AUTOSAR XML (schema 4-3-0)
package /Impl_SWC_HALIN_ARPkg
  swc implementation Impl_SWC_HALIN_type: programming-language=C, sw-version=1.0.0, vendor-id=0, behavior=SWC_HALIN_type_IB
    code-descriptors:
      code SRC: artifact-descriptors=autosar-engineering-object={short-label=EngObject, category=SWSRC}
    resource consumption ResourceConsumption
      memory section Mem_SWC_HALIN_CAL: size=0, sw-addrmethod=CAL, symbol=CAL
      memory section Mem_SWC_HALIN_CODE: size=0, sw-addrmethod=CODE, symbol=CODE
package /Impl_Type_HALIN_ARPkg
  6 x impl type:
    BHAL_CAN1_outputs: category=STRUCTURE
      63 x element, all with category=TYPE_REFERENCE:
        VHAL_CANMsgInvalidACBTMSC10000_flg: implementation-data-type=boolean
        VHAL_ACAmbTemp_C: implementation-data-type=float32
        VHAL_CANMsgInvalidACBTMSC10001_flg: implementation-data-type=boolean
        VHAL_ACFanSpdSta_enum: implementation-data-type=uint8
        VHAL_CANMsgInvalidACBTMSC10004_flg: implementation-data-type=boolean
        VHAL_TM2BFaultCode_enum: implementation-data-type=uint8
        VHAL_CANMsgInvalidACBTMSC50000_flg: implementation-data-type=boolean
        VHAL_ACTempSetSta_C: implementation-data-type=float32
        VHAL_CANMsgInvalidASC1A_flg: implementation-data-type=boolean
        VHAL_ASC1KneelingInfo_enum: implementation-data-type=uint8
        VHAL_CANMsgInvalidEBC1_flg: implementation-data-type=boolean
        VHAL_ABSFullyOper_enum: implementation-data-type=uint8
        VHAL_ABSOffroadSw_enum: implementation-data-type=uint8
        VHAL_ASRBrakeCtrlAtc_enum: implementation-data-type=uint8
        VHAL_ASREngCtrlAtc_enum: implementation-data-type=uint8
        VHAL_ASRHillHolderSw_enum: implementation-data-type=uint8
        VHAL_ASROffroadSw_enum: implementation-data-type=uint8
        VHAL_ATCASRInfoSig_enum: implementation-data-type=uint8
        VHAL_AcltrInterlockSw_enum: implementation-data-type=uint8
        VHAL_AntiLBrakABSAct_enum: implementation-data-type=uint8
        VHAL_BrakePedalPos_pct: implementation-data-type=float32
        VHAL_EBSAmWarnLampSta_enum: implementation-data-type=uint8
        VHAL_EBSBrakeSw_enum: implementation-data-type=uint8
        VHAL_EBSRedWarnLampSta_enum: implementation-data-type=uint8
        VHAL_EngAuxShutdownSw_enum: implementation-data-type=uint8
        VHAL_EngDerateSw_enum: implementation-data-type=uint8
        VHAL_EngRetSel_pct: implementation-data-type=float32
        VHAL_HaltBrakeSw_enum: implementation-data-type=uint8
        VHAL_RmAccelEnSw_enum: implementation-data-type=uint8
        VHAL_SACtrlBrakeCtrl_SA: implementation-data-type=float32
        VHAL_TractCtrlOvrSw_enum: implementation-data-type=uint8
        VHAL_TrailerABSSta_enum: implementation-data-type=uint8
        VHAL_TrailerABSWarnSig_enum: implementation-data-type=uint8
        VHAL_CANMsgInvalidEBC2_flg: implementation-data-type=boolean
        VHAL_FASpeed_kph: implementation-data-type=float32
        VHAL_RelaSpdFALWheel_kph: implementation-data-type=float32
        VHAL_RelaSpdFARWheel_kph: implementation-data-type=float32
        VHAL_CANMsgInvalidEBC5_flg: implementation-data-type=boolean
        VHAL_BrkTempeWarn_enum: implementation-data-type=uint8
        VHAL_FndBrkUse_enum: implementation-data-type=uint8
        VHAL_HaltBrkMode_enum: implementation-data-type=uint8
        VHAL_HillHolderMode_enum: implementation-data-type=uint8
        VHAL_ParkBrkActuFAct_enum: implementation-data-type=uint8
        VHAL_XBRAcltnLimit_mps2: implementation-data-type=float32
        VHAL_XBRActtrlMode_enum: implementation-data-type=uint8
        VHAL_XBRSysSta_enum: implementation-data-type=uint8
        VHAL_CANMsgInvalidECASDM1_flg: implementation-data-type=boolean
        VHAL_ECASAWarmLampSta_enum: implementation-data-type=uint8
        VHAL_CANMsgInvalidEMC1EM1_flg: implementation-data-type=boolean
        VHAL_EM1CS_enum: implementation-data-type=uint8
        VHAL_EM1Cnt_enum: implementation-data-type=uint8
        VHAL_EM1OvrCtrlMBrk_enum: implementation-data-type=uint8
        VHAL_EM1OvrCtrlMDriv_enum: implementation-data-type=uint8
        VHAL_EM1OvrCtrlMPriBrk_enum: implementation-data-type=uint8
        VHAL_EM1ReqTorqHRlsBrk_pct: implementation-data-type=float32
        VHAL_EM1ReqTorqHRlsDri_pct: implementation-data-type=float32
        VHAL_EM1ReqTorqLimBrk_pct: implementation-data-type=float32
        VHAL_EM1ReqTorqLimDriv_pct: implementation-data-type=float32
        VHAL_CANMsgInvalidHRW_flg: implementation-data-type=boolean
        VHAL_WhlSpeedFL_kph: implementation-data-type=float32
        VHAL_CANMsgInvalidTC1_flg: implementation-data-type=boolean
        VHAL_DrivDirF_enum: implementation-data-type=uint8
        VHAL_TransReqGear_enum: implementation-data-type=uint8
    BHAL_CAN2_outputs: category=STRUCTURE
      element VHAL_CANMsgInvalidIVIC1000_flg: implementation-data-type=boolean
      element VHAL_IVIACFanSpdReqCmd_enum: implementation-data-type=uint8
    BHAL_CAN3_outputs: category=STRUCTURE
      49 x element, all with category=TYPE_REFERENCE:
        VHAL_CANMsgInvalidB2TMInfo_flg: implementation-data-type=boolean
        VHAL_B2THVRlySta_enum: implementation-data-type=uint8
        VHAL_CANMsgInvalidB2VBattInfo1_flg: implementation-data-type=boolean
        VHAL_B2VBI1BattType_enum: implementation-data-type=uint8
        VHAL_CANMsgInvalidB2VCurrentLimit_flg: implementation-data-type=boolean
        VHAL_B2VAPlsDischgCurr_A: implementation-data-type=float32
        VHAL_B2VAvaPlsChgCurr_A: implementation-data-type=float32
        VHAL_CANMsgInvalidB2VFult132960_flg: implementation-data-type=boolean
        VHAL_B2VHVILFault_flg: implementation-data-type=boolean
        VHAL_CANMsgInvalidB2VST1_flg: implementation-data-type=boolean
        VHAL_B2VACChgConnSta_flg: implementation-data-type=boolean
        VHAL_B2VACChgNegRlySta_enum: implementation-data-type=uint8
        VHAL_B2VACChgPosRlySta_enum: implementation-data-type=uint8
        VHAL_B2VBMUHVSta_enum: implementation-data-type=uint8
        VHAL_B2VChgMode_enum: implementation-data-type=uint8
        VHAL_B2VChgSta_enum: implementation-data-type=uint8
        VHAL_B2VDCChgConnSta_enum: implementation-data-type=uint8
        VHAL_B2VDCChgN1RlySta_enum: implementation-data-type=uint8
        VHAL_B2VDCChgP1RlySta_enum: implementation-data-type=uint8
        VHAL_B2VMainNegRlySta_enum: implementation-data-type=uint8
        VHAL_CANMsgInvalidB2VST2_flg: implementation-data-type=boolean
        VHAL_B2VFaultCode_enum: implementation-data-type=uint8
        VHAL_B2VFaultLv_enum: implementation-data-type=uint8
        VHAL_B2VPackCurr_A: implementation-data-type=float32
        VHAL_B2VPackInsideVol_V: implementation-data-type=float32
        VHAL_B2VRqHVPwrOff_enum: implementation-data-type=uint8
        VHAL_B2VSOC_pct: implementation-data-type=float32
        VHAL_CANMsgInvalidB2VST4_flg: implementation-data-type=boolean
        VHAL_B2VMinTempPos_enum: implementation-data-type=uint8
        VHAL_CANMsgInvalidB2VST5_flg: implementation-data-type=boolean
        VHAL_B2VCellMinVol_V: implementation-data-type=float32
        VHAL_CANMsgInvalidEWP1_flg: implementation-data-type=boolean
        VHAL_EWPPEFault_enum: implementation-data-type=uint8
        VHAL_CANMsgInvalidTMMCUSta1_flg: implementation-data-type=boolean
        VHAL_AtvDisChgEnFbk_flg: implementation-data-type=boolean
        VHAL_MCUCtrlMdSta_enum: implementation-data-type=uint8
        VHAL_MCUIGBTEnFbk_flg: implementation-data-type=boolean
        VHAL_MotorSpd_rpm: implementation-data-type=float32
        VHAL_MotorTrq_Nm: implementation-data-type=float32
        VHAL_CANMsgInvalidTMMCUSta2_flg: implementation-data-type=boolean
        VHAL_MCUFailGrade_enum: implementation-data-type=uint8
        VHAL_MCUTemp_C: implementation-data-type=float32
        VHAL_MCUTrqLimHi_Nm: implementation-data-type=float32
        VHAL_MCUTrqLimLo_Nm: implementation-data-type=float32
        VHAL_MotorTemp_C: implementation-data-type=float32
        VHAL_CANMsgInvalidTMMCUSta3_flg: implementation-data-type=boolean
        VHAL_MCUDCCur_A: implementation-data-type=float32
        VHAL_MCUDCVol_V: implementation-data-type=float32
        VHAL_MCUFailCode_enum: implementation-data-type=uint8
    BHAL_CAN4_outputs: category=STRUCTURE
      51 x element, all with category=TYPE_REFERENCE:
        VHAL_CANMsgInvalidZFRC1000_flg: implementation-data-type=boolean
        VHAL_ParkBrakeSW_enum: implementation-data-type=uint8
        VHAL_CANMsgInvalidZFRCE1000_flg: implementation-data-type=boolean
        VHAL_AirPressureFC2_kPa: implementation-data-type=float32
        VHAL_ZFRBCMAutoLightSWSta_flg: implementation-data-type=boolean
        VHAL_ZFRBCMBrakeSta_flg: implementation-data-type=boolean
        VHAL_ZFRBCMHBeamSWSta_flg: implementation-data-type=boolean
        VHAL_ZFRBCMHeadLpSWSta_flg: implementation-data-type=boolean
        VHAL_ZFRBCMLFTurnLpCSta_A: implementation-data-type=float32
        VHAL_ZFRBCMLightSensorVSta_V: implementation-data-type=float32
        VHAL_ZFRBCMPLampSta_flg: implementation-data-type=boolean
        VHAL_ZFRBCMRFTurnLpCSta_A: implementation-data-type=float32
        VHAL_ZFRBCMRFogLpSWSta_flg: implementation-data-type=boolean
        VHAL_ZFRBCMSeatbeltSta_flg: implementation-data-type=boolean
        VHAL_ZFRBCMWasherSWSta_flg: implementation-data-type=boolean
        VHAL_ZFRBCMWiperASSta_flg: implementation-data-type=boolean
        VHAL_ZFRBCMWiperHSWSta_flg: implementation-data-type=boolean
        VHAL_ZFRBCMWiperLSWSta_flg: implementation-data-type=boolean
        VHAL_CANMsgInvalidZRRCE1000_flg: implementation-data-type=boolean
        VHAL_ZRRBCMAllDoorSta_enum: implementation-data-type=uint8
        VHAL_CANMsgInvalidZRRCE1001_flg: implementation-data-type=boolean
        VHAL_AirPressurePC3_kPa: implementation-data-type=float32
        VHAL_AirPressureRC1_kPa: implementation-data-type=float32
        VHAL_FDCCHASSISVCUEACPressSta_flg: implementation-data-type=boolean
        VHAL_ZRRBCMCallingSWSta_flg: implementation-data-type=boolean
        VHAL_ZRRBCMLRTurnLpCSta_A: implementation-data-type=float32
        VHAL_ZRRBCMPLampSta_flg: implementation-data-type=boolean
        VHAL_ZRRBCMRRTurnLpCSta_A: implementation-data-type=float32
        VHAL_ZRRBCMSTOPSW2Sta_flg: implementation-data-type=boolean
        VHAL_ZRRBCMSTOPSWSta_flg: implementation-data-type=boolean
        VHAL_CANMsgInvalidzGWCANRr1C500_flg: implementation-data-type=boolean
        VHAL_DCDCEnSta_enum: implementation-data-type=uint8
        VHAL_DCDCErrLvSta_enum: implementation-data-type=uint8
        VHAL_DCDCOutVolSta_V: implementation-data-type=float32
        VHAL_DCDCTempSta_C: implementation-data-type=float32
        VHAL_EACEnSta_enum: implementation-data-type=uint8
        VHAL_EACErrLvSta_enum: implementation-data-type=uint8
        VHAL_EACInvTempSta_C: implementation-data-type=float32
        VHAL_EHPSEnSta_enum: implementation-data-type=uint8
        VHAL_EHPSErrLvSta_enum: implementation-data-type=uint8
        VHAL_EHPSInvTempSta_C: implementation-data-type=float32
        VHAL_EHPSMotorSpdSta_rpm: implementation-data-type=float32
        VHAL_PDUACRlySta_enum: implementation-data-type=uint8
        VHAL_PDUDCDCEACEHPSHVLoopSta_enum: implementation-data-type=uint8
        VHAL_PDUDCDCEACEHPSPreRlySta_enum: implementation-data-type=uint8
        VHAL_PDUDCDCEACEHPSRlySta_enum: implementation-data-type=uint8
        VHAL_PDUHVILSta_enum: implementation-data-type=uint8
        VHAL_PDUMCUHVLoopSta_enum: implementation-data-type=uint8
        VHAL_PDUMCUPosRlySta_enum: implementation-data-type=uint8
        VHAL_PDUMCUPreRlySta_enum: implementation-data-type=uint8
        VHAL_PDUSelfChkSta_enum: implementation-data-type=uint8
    u8_Array16_type: category=ARRAY
      element u8_Array16: category=VALUE, array-size=16, array-size-semantics=FIXED-SIZE, base-type=uint8
    u8_Array8_type: category=ARRAY
      element u8_Array8: category=VALUE, array-size=8, array-size-semantics=FIXED-SIZE, base-type=uint8
package /Interface_HALIN_ARPkg
  4 x sender receiver interface:
    IF_BHAL_CAN1_outputs
      data BHAL_CAN1_outputs: type=BHAL_CAN1_outputs
    IF_BHAL_CAN2_outputs
      data BHAL_CAN2_outputs: type=BHAL_CAN2_outputs
    IF_BHAL_CAN3_outputs
      data BHAL_CAN3_outputs: type=BHAL_CAN3_outputs
    IF_BHAL_CAN4_outputs
      data BHAL_CAN4_outputs: type=BHAL_CAN4_outputs
package /SWC_HALIN_ARPkg
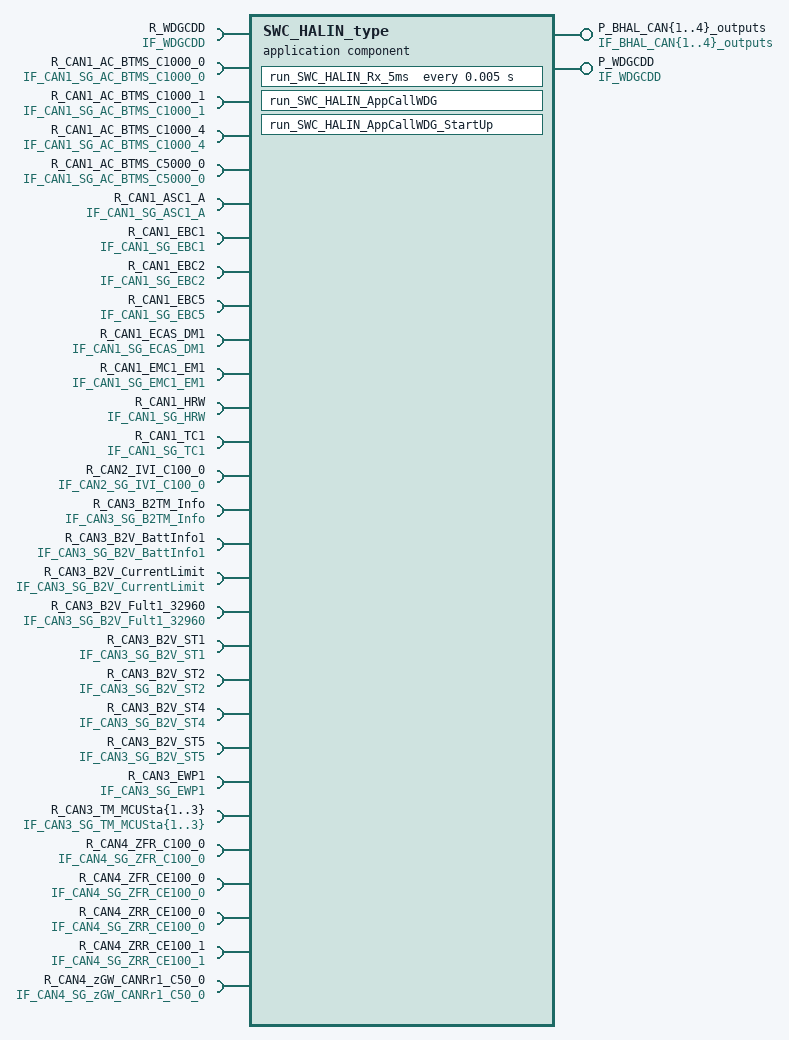
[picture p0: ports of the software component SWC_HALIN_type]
  application sw component type SWC_HALIN_type
    5 x provide port:
      P_BHAL_CAN{1..4}_outputs: provided-interface=IF_BHAL_CAN{1..4}_outputs
      P_WDGCDD: provided-interface=IF_WDGCDD
    31 x require port:
      R_WDGCDD: required-interface=IF_WDGCDD
      R_CAN1_AC_BTMS_C1000_0: required-interface=IF_CAN1_SG_AC_BTMS_C1000_0
      R_CAN1_AC_BTMS_C1000_1: required-interface=IF_CAN1_SG_AC_BTMS_C1000_1
      R_CAN1_AC_BTMS_C1000_4: required-interface=IF_CAN1_SG_AC_BTMS_C1000_4
      R_CAN1_AC_BTMS_C5000_0: required-interface=IF_CAN1_SG_AC_BTMS_C5000_0
      R_CAN1_ASC1_A: required-interface=IF_CAN1_SG_ASC1_A
      R_CAN1_EBC1: required-interface=IF_CAN1_SG_EBC1
      R_CAN1_EBC2: required-interface=IF_CAN1_SG_EBC2
      R_CAN1_EBC5: required-interface=IF_CAN1_SG_EBC5
      R_CAN1_ECAS_DM1: required-interface=IF_CAN1_SG_ECAS_DM1
      R_CAN1_EMC1_EM1: required-interface=IF_CAN1_SG_EMC1_EM1
      R_CAN1_HRW: required-interface=IF_CAN1_SG_HRW
      R_CAN1_TC1: required-interface=IF_CAN1_SG_TC1
      R_CAN2_IVI_C100_0: required-interface=IF_CAN2_SG_IVI_C100_0
      R_CAN3_B2TM_Info: required-interface=IF_CAN3_SG_B2TM_Info
      R_CAN3_B2V_BattInfo1: required-interface=IF_CAN3_SG_B2V_BattInfo1
      R_CAN3_B2V_CurrentLimit: required-interface=IF_CAN3_SG_B2V_CurrentLimit
      R_CAN3_B2V_Fult1_32960: required-interface=IF_CAN3_SG_B2V_Fult1_32960
      R_CAN3_B2V_ST1: required-interface=IF_CAN3_SG_B2V_ST1
      R_CAN3_B2V_ST2: required-interface=IF_CAN3_SG_B2V_ST2
      R_CAN3_B2V_ST4: required-interface=IF_CAN3_SG_B2V_ST4
      R_CAN3_B2V_ST5: required-interface=IF_CAN3_SG_B2V_ST5
      R_CAN3_EWP1: required-interface=IF_CAN3_SG_EWP1
      R_CAN3_TM_MCUSta{1..3}: required-interface=IF_CAN3_SG_TM_MCUSta{1..3}
      R_CAN4_ZFR_C100_0: required-interface=IF_CAN4_SG_ZFR_C100_0
      R_CAN4_ZFR_CE100_0: required-interface=IF_CAN4_SG_ZFR_CE100_0
      R_CAN4_ZRR_CE100_0: required-interface=IF_CAN4_SG_ZRR_CE100_0
      R_CAN4_ZRR_CE100_1: required-interface=IF_CAN4_SG_ZRR_CE100_1
      R_CAN4_zGW_CANRr1_C50_0: required-interface=IF_CAN4_SG_zGW_CANRr1_C50_0
    behavior SWC_HALIN_type_IB: handle-termination-and-restart=NO-SUPPORT, port-api-option{enable-take-address=false, indirect-api=false, port=P_WDGCDD}
      timing event TE_HALIN_5ms: start-on-event=run_SWC_HALIN_Rx_5ms, period=0.005
      operation invoked event oie_P_WDGCDD_CSOP_Call_WDG_AppStart: start-on-event=run_SWC_HALIN_AppCallWDG_StartUp, operation=P_WDGCDD.CSOP_Call_WDG_AppStart
      operation invoked event oie_P_WDGCDD_CSOP_Call_Watchdog: start-on-event=run_SWC_HALIN_AppCallWDG, operation=P_WDGCDD.CSOP_Call_Watchdog
      runnable run_SWC_HALIN_Rx_5ms
        data-receive-point-by-arguments:
          30 x access:
            drparg_CAN1_SG_AC_BTMS_C1000_0: accessed-variable=R_CAN1_AC_BTMS_C1000_0.CAN1_SG_AC_BTMS_C1000_0
            drparg_CAN1_SG_AC_BTMS_C1000_1: accessed-variable=R_CAN1_AC_BTMS_C1000_1.CAN1_SG_AC_BTMS_C1000_1
            drparg_CAN1_SG_AC_BTMS_C1000_4: accessed-variable=R_CAN1_AC_BTMS_C1000_4.CAN1_SG_AC_BTMS_C1000_4
            drparg_CAN1_SG_AC_BTMS_C5000_0: accessed-variable=R_CAN1_AC_BTMS_C5000_0.CAN1_SG_AC_BTMS_C5000_0
            drparg_CAN1_SG_ASC1_A: accessed-variable=R_CAN1_ASC1_A.CAN1_SG_ASC1_A
            drparg_CAN1_SG_EBC1: accessed-variable=R_CAN1_EBC1.CAN1_SG_EBC1
            drparg_CAN1_SG_EBC2: accessed-variable=R_CAN1_EBC2.CAN1_SG_EBC2
            drparg_CAN1_SG_EBC5: accessed-variable=R_CAN1_EBC5.CAN1_SG_EBC5
            drparg_CAN1_SG_ECAS_DM1: accessed-variable=R_CAN1_ECAS_DM1.CAN1_SG_ECAS_DM1
            drparg_CAN1_SG_EMC1_EM1: accessed-variable=R_CAN1_EMC1_EM1.CAN1_SG_EMC1_EM1
            drparg_CAN1_SG_HRW: accessed-variable=R_CAN1_HRW.CAN1_SG_HRW
            drparg_CAN1_SG_TC1: accessed-variable=R_CAN1_TC1.CAN1_SG_TC1
            drparg_CAN2_SG_IVI_C100_0: accessed-variable=R_CAN2_IVI_C100_0.CAN2_SG_IVI_C100_0
            drparg_CAN3_SG_B2TM_Info: accessed-variable=R_CAN3_B2TM_Info.CAN3_SG_B2TM_Info
            drparg_CAN3_SG_B2V_BattInfo1: accessed-variable=R_CAN3_B2V_BattInfo1.CAN3_SG_B2V_BattInfo1
            drparg_CAN3_SG_B2V_CurrentLimit: accessed-variable=R_CAN3_B2V_CurrentLimit.CAN3_SG_B2V_CurrentLimit
            drparg_CAN3_SG_B2V_Fult1_32960: accessed-variable=R_CAN3_B2V_Fult1_32960.CAN3_SG_B2V_Fult1_32960
            drparg_CAN3_SG_B2V_ST1: accessed-variable=R_CAN3_B2V_ST1.CAN3_SG_B2V_ST1
            drparg_CAN3_SG_B2V_ST2: accessed-variable=R_CAN3_B2V_ST2.CAN3_SG_B2V_ST2
            drparg_CAN3_SG_B2V_ST4: accessed-variable=R_CAN3_B2V_ST4.CAN3_SG_B2V_ST4
            drparg_CAN3_SG_B2V_ST5: accessed-variable=R_CAN3_B2V_ST5.CAN3_SG_B2V_ST5
            drparg_CAN3_SG_EWP1: accessed-variable=R_CAN3_EWP1.CAN3_SG_EWP1
            drparg_CAN3_SG_TM_MCUSta{1..3}: accessed-variable=R_CAN3_TM_MCUSta{1..3}.CAN3_SG_TM_MCUSta{1..3}
            drparg_CAN4_SG_ZFR_C100_0: accessed-variable=R_CAN4_ZFR_C100_0.CAN4_SG_ZFR_C100_0
            drparg_CAN4_SG_ZFR_CE100_0: accessed-variable=R_CAN4_ZFR_CE100_0.CAN4_SG_ZFR_CE100_0
            drparg_CAN4_SG_ZRR_CE100_0: accessed-variable=R_CAN4_ZRR_CE100_0.CAN4_SG_ZRR_CE100_0
            drparg_CAN4_SG_ZRR_CE100_1: accessed-variable=R_CAN4_ZRR_CE100_1.CAN4_SG_ZRR_CE100_1
            drparg_CAN4_SG_zGW_CANRr1_C50_0: accessed-variable=R_CAN4_zGW_CANRr1_C50_0.CAN4_SG_zGW_CANRr1_C50_0
        data-send-points:
          4 x access:
            dsp_BHAL_CAN{1..4}_outputs: accessed-variable=P_BHAL_CAN{1..4}_outputs.BHAL_CAN{1..4}_outputs
        sync call scp_CSOP_Call_WDG_AppStart: operation=R_WDGCDD.CSOP_Call_WDG_AppStart, timeout=0.0
        sync call scp_CSOP_Call_Watchdog: operation=R_WDGCDD.CSOP_Call_Watchdog, timeout=0.0
      runnable run_SWC_HALIN_AppCallWDG
      runnable run_SWC_HALIN_AppCallWDG_StartUp
